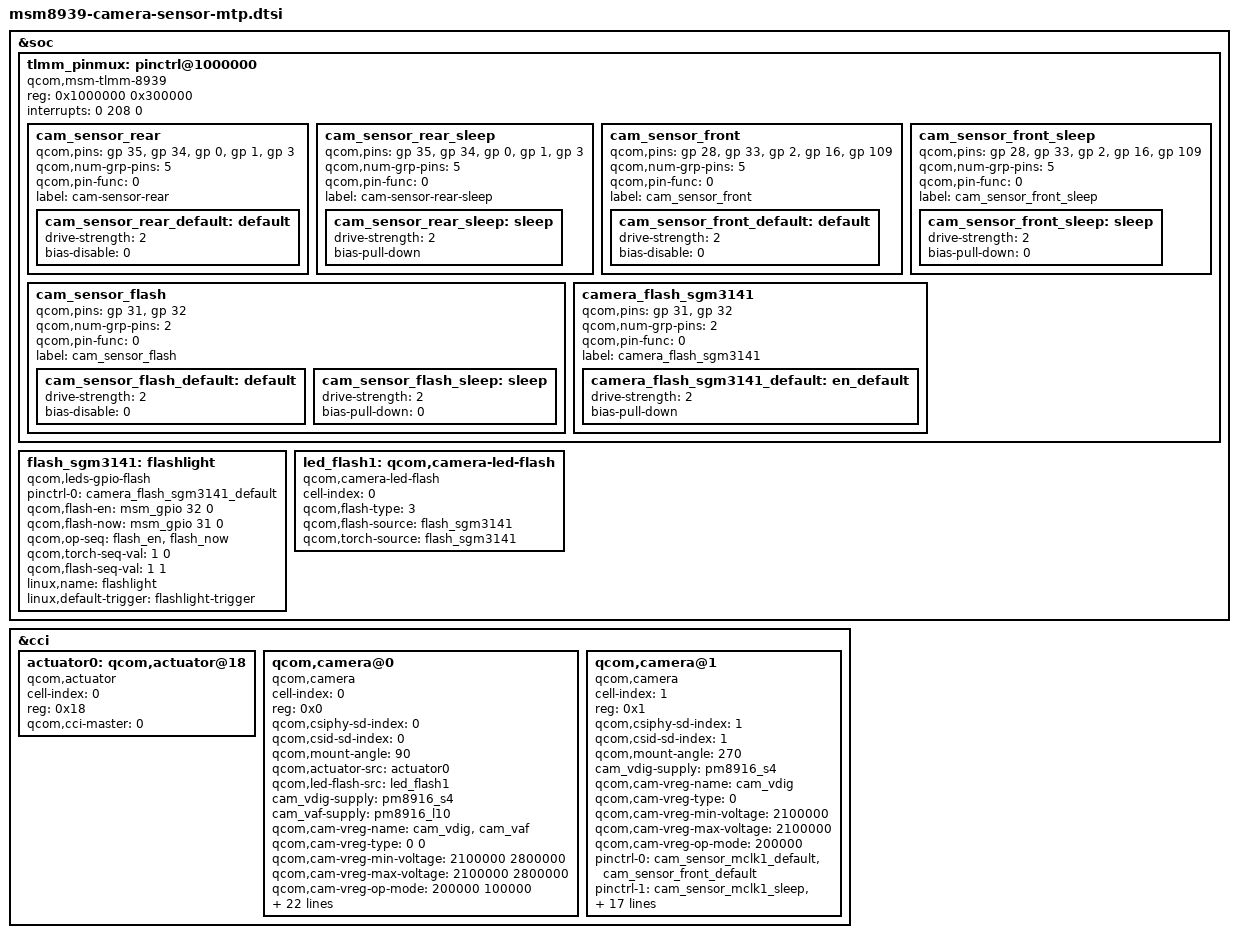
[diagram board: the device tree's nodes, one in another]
/*
 * Copyright (c) 2014, The Linux Foundation. All rights reserved.
 *
 * This program is free software; you can redistribute it and/or modify
 * it under the terms of the GNU General Public License version 2 and
 * only version 2 as published by the Free Software Foundation.
 *
 * This program is distributed in the hope that it will be useful,
 * but WITHOUT ANY WARRANTY; without even the implied warranty of
 * MERCHANTABILITY or FITNESS FOR A PARTICULAR PURPOSE.  See the
 * GNU General Public License for more details.
 */
	
&tlmm_pinmux {
 	camera_flash_sgm3141 {
 		/* FLSH_RESET,FLASH_EN,FLASH_NOW */
 		qcom,pins = <&gp 31>,<&gp 32> ;
 		qcom,num-grp-pins = <2>;
 		qcom,pin-func = <0>;
 		label = "camera_flash_sgm3141";
 		/* active state */
 		camera_flash_sgm3141_default: en_default {
 			drive-strength = <2>; /* 2 MA */
 			bias-pull-down;
 		};
 	};
};

&soc {
	tlmm_pinmux: pinctrl@1000000 {
		compatible = "qcom,msm-tlmm-8939", "qcom,msm-tlmm-8916";
		reg = <0x1000000 0x300000>;
		interrupts = <0 208 0>;

		cam_sensor_rear {
			/* RESET, STANDBY */
			qcom,pins =  <&gp 35>, <&gp 34>, <&gp 0>, <&gp 1>, <&gp 3>; /*add gp 0 1 3 by congshan */
			qcom,num-grp-pins = <5>;
			qcom,pin-func = <0>;
			label = "cam-sensor-rear";
			/* active state */
			cam_sensor_rear_default: default {
				drive-strength = <2>; /* 2 MA */
				bias-disable = <0>; /* No PULL */
			};
		};

		cam_sensor_rear_sleep {
			/* RESET, STANDBY */
			qcom,pins =  <&gp 35>, <&gp 34>, <&gp 0>, <&gp 1>, <&gp 3>; /*add gp 0 1 3 by congshan */
			qcom,num-grp-pins = <5>;
			qcom,pin-func = <0>;
			label = "cam-sensor-rear-sleep";
			/*suspend state */
			cam_sensor_rear_sleep: sleep {
				drive-strength = <2>; /* 2 MA */
				bias-pull-down; /* PULL DOWN */
			};
		};

		cam_sensor_front {
			/* RESET, STANDBY */
			qcom,pins = <&gp 28>, <&gp 33>, <&gp 2>, <&gp 16>, <&gp 109>; /*add gp 2 16 109 by congshan */
			qcom,num-grp-pins = <5>;
			qcom,pin-func = <0>;
			label = "cam_sensor_front";
			/* active state */
			cam_sensor_front_default: default {
				drive-strength = <2>; /* 2 MA */
				bias-disable = <0>; /* No PULL */
			};
		};

		cam_sensor_front_sleep {
			/* RESET, STANDBY */
			qcom,pins = <&gp 28>, <&gp 33>, <&gp 2>, <&gp 16>, <&gp 109>; /*add gp 2 16 109 by congshan */
			qcom,num-grp-pins = <5>;
			qcom,pin-func = <0>;
			label = "cam_sensor_front_sleep";
			/*suspend state */
			cam_sensor_front_sleep: sleep {
				drive-strength = <2>; /* 2 MA */
				bias-pull-down = <0>; /* PULL DOWN */
			};
		};

		cam_sensor_flash {
			/* FLSH_RESET,FLASH_EN,FLASH_NOW */
			qcom,pins =  <&gp 31>,<&gp 32> ;//change by congshan
			qcom,num-grp-pins = <2>;
			qcom,pin-func = <0>;
			label = "cam_sensor_flash";
			/* active state */
			cam_sensor_flash_default: default {
				drive-strength = <2>; /* 2 MA */
				bias-disable = <0>; /* No PULL */
			};
			/*suspended state */
			cam_sensor_flash_sleep: sleep {
				drive-strength = <2>; /* 2 MA */
				bias-pull-down = <0>; /* PULL DOWN */
			};
		};
	};
 	flash_sgm3141:flashlight {
 		compatible = "qcom,leds-gpio-flash";
 		status = "okay";
 		pinctrl-names = "flash_default";
 		pinctrl-0 = <&camera_flash_sgm3141_default>;
 		qcom,flash-en = <&msm_gpio 32 0>;
 		qcom,flash-now = <&msm_gpio 31 0>;
		qcom,op-seq = "flash_en", "flash_now";
		qcom,torch-seq-val = <1 0>;
		qcom,flash-seq-val = <1 1>;
 		linux,name = "flashlight";
 		linux,default-trigger = "flashlight-trigger";
 	};

 	led_flash1: qcom,camera-led-flash {
 		cell-index = <0>;
 		compatible = "qcom,camera-led-flash";
 		qcom,flash-type = <3>;
 		qcom,flash-source = <&flash_sgm3141>;
 		qcom,torch-source = <&flash_sgm3141>;
 	};
};

&cci {
	actuator0: qcom,actuator@18 {
		cell-index = <0>;
		reg = <0x18>;
		compatible = "qcom,actuator";
		qcom,cci-master = <0>;
	};	

/*
	 eeprom0: qcom,eeprom@20 {
		cell-index = <0>;
		reg = <0x20>;
		qcom,eeprom-name = "sonyimx135";
		compatible = "qcom,eeprom";
		qcom,slave-addr = <0x20>;
		qcom,cci-master = <0>;
		qcom,num-blocks = <16>;

		qcom,page0 = <1 0x3b02 2 0x10 1 5>;
		qcom,pageen0 = <1 0x3b00 2 0x01 1 5>;
		qcom,poll0 = <1 0x3b01 2 0x01 1 5>;
		qcom,mem0 = <8 0x3b04 2 0 1 0>;

		qcom,page1 = <1 0x3b02 2 0x0F 1 5>;
		qcom,pageen1 = <1 0x3b00 2 0x01 1 5>;
		qcom,poll1 = <1 0x3b01 2 0x01 1 5>;
		qcom,mem1 = <8 0x3b04 2 0 1 0>;

		qcom,page2 = <1 0x3b02 2 0x0E 1 5>;
		qcom,pageen2 = <1 0x3b00 2 0x01 1 5>;
		qcom,poll2 = <1 0x3b01 2 0x01 1 5>;
		qcom,mem2 = <8 0x3b04 2 0 1 0>;

		qcom,page3 = <1 0x3b02 2 0x0D 1 5>;
		qcom,pageen3 = <1 0x3b00 2 0x01 1 5>;
		qcom,poll3 = <1 0x3b01 2 0x01 1 5>;
		qcom,mem3 = <8 0x3b04 2 0 1 0>;

		qcom,page4 = <1 0x3b02 2 0x12 1 5>;
		qcom,pageen4 = <1 0x3b00 2 0x01 1 5>;
		qcom,poll4 = <1 0x3b01 2 0x01 1 5>;
		qcom,mem4 = <7 0x3b09 2 0 1 0>;

		qcom,page5 = <1 0x3b02 2 0x11 1 5>;
		qcom,pageen5 = <1 0x3b00 2 0x01 1 5>;
		qcom,poll5 = <1 0x3b01 2 0x01 1 5>;
		qcom,mem5 = <7 0x3b09 2 0 1 0>;

		qcom,page6 = <1 0x3b02 2 0x10 1 5>;
		qcom,pageen6 = <1 0x3b00 2 0x01 1 5>;
		qcom,poll6 = <1 0x3b01 2 0x01 1 5>;
		qcom,mem6 = <7 0x3b09 2 0 1 0>;

		qcom,page7 = <1 0x3b02 2 0x09 1 5>;
		qcom,pageen7 = <1 0x3b00 2 0x01 1 5>;
		qcom,poll7 = <1 0x3b01 2 0x01 1 5>;
		qcom,mem7 = <7 0x3b09 2 0 1 0>;

		qcom,page8 = <1 0x3b02 2 0x01 1 5>;
		qcom,pageen8 = <1 0x3b00 2 0x01 1 5>;
		qcom,poll8 = <1 0x3b01 2 0x01 1 5>;
		qcom,mem8 = <64 0x3b04 2 0 1 0>;

		qcom,page9 = <1 0x3b02 2 0x02 1 5>;
		qcom,pageen9 = <1 0x3b00 2 0x01 1 5>;
		qcom,poll9 = <1 0x3b01 2 0x01 1 5>;
		qcom,mem9 = <64 0x3b04 2 0 1 0>;

		qcom,page10 = <1 0x3b02 2 0x03 1 5>;
		qcom,pageen10 = <1 0x3b00 2 0x01 1 5>;
		qcom,poll10 = <1 0x3b01 2 0x01 1 5>;
		qcom,mem10 = <64 0x3b04 2 0 1 0>;

		qcom,page11 = <1 0x3b02 2 0x04 1 5>;
		qcom,pageen11 = <1 0x3b00 2 0x01 1 5>;
		qcom,poll11 = <1 0x3b01 2 0x01 1 5>;
		qcom,mem11 = <64 0x3b04 2 0 1 0>;

		qcom,page12 = <1 0x3b02 2 0x05 1 5>;
		qcom,pageen12 = <1 0x3b00 2 0x01 1 5>;
		qcom,poll12 = <1 0x3b01 2 0x01 1 5>;
		qcom,mem12 = <64 0x3b04 2 0 1 0>;

		qcom,page13 = <1 0x3b02 2 0x06 1 5>;
		qcom,pageen13 = <1 0x3b00 2 0x01 1 5>;
		qcom,poll13 = <1 0x3b01 2 0x01 1 5>;
		qcom,mem13 = <64 0x3b04 2 0 1 0>;

		qcom,page14 = <1 0x3b02 2 0x07 1 5>;
		qcom,pageen14 = <1 0x3b00 2 0x01 1 5>;
		qcom,poll14 = <1 0x3b01 2 0x01 1 5>;
		qcom,mem14 = <64 0x3b04 2 0 1 0>;

		qcom,page15 = <1 0x3b02 2 0x08 1 5>;
		qcom,pageen15 = <1 0x3b00 2 0x01 1 5>;
		qcom,poll15 = <1 0x3b01 2 0x01 1 5>;
		qcom,mem15 = <56 0x3b04 2 0 1 0>;

		cam_vdig-supply = <&pm8916_s4>;
		cam_vio-supply = <&pm8916_l17>;
		cam_vana-supply = <&pm8916_l6>;
		qcom,cam-vreg-name = "cam_vdig", "cam_vio", "cam_vana";
		qcom,cam-vreg-type = <0 1 0>;
		qcom,cam-vreg-min-voltage = <2100000 0 2850000 2800000>;
		qcom,cam-vreg-max-voltage = <2100000 0 2850000 2800000>;
		qcom,cam-vreg-op-mode = <200000 0 80000 100000>;
		pinctrl-names = "cam_default", "cam_suspend";
		pinctrl-0 = <&cam_sensor_mclk0_default &cam_sensor_rear_default>;
		pinctrl-1 = <&cam_sensor_mclk0_sleep &cam_sensor_rear_sleep>;
		qcom,gpio-no-mux = <0>;
		gpios = <&msm_gpio 26 0>,
			<&msm_gpio 35 0>,
			<&msm_gpio 34 0>;
		qcom,gpio-reset = <1>;
		qcom,gpio-standby = <2>;
		qcom,gpio-req-tbl-num = <0 1 2>;
		qcom,gpio-req-tbl-flags = <1 0 0>;
		qcom,gpio-req-tbl-label = "CAMIF_MCLK",
			"CAM_RESET1",
			"CAM_STANDBY";
		qcom,gpio-set-tbl-num = <1 1>;
		qcom,gpio-set-tbl-flags = <0 2>;
		qcom,gpio-set-tbl-delay = <1000 4000>;
		qcom,csi-lane-assign = <0x4320>;
		qcom,csi-lane-mask = <0x3>;
		qcom,cam-power-seq-type = "sensor_vreg", "sensor_vreg", "sensor_vreg",
			"sensor_gpio", "sensor_gpio" , "sensor_clk";
		qcom,cam-power-seq-val = "cam_vdig", "cam_vana", "cam_vio",
			"sensor_gpio_reset", "sensor_gpio_standby","sensor_cam_mclk";
		qcom,cam-power-seq-cfg-val = <1 1 1 1 1 24000000>;
		qcom,cam-power-seq-delay = <1 1 1 30 30 5>;
	};*/
/*
	//added by congshan start
	eeprom0: qcom,eeprom@20 {
		cell-index = <0>;
		reg = <0x20>;
		qcom,eeprom-name = "zte_imx135_bu64291gwz";
		compatible = "qcom,eeprom";
		qcom,slave-addr = <0x20>;
		qcom,cci-master = <0>;
		qcom,num-blocks = <6>;
		qcom,page0 = <0 0x00 1 0xf 1 1>;
		qcom,poll0 = <0 0x0 2 0 1 1>;
		qcom,saddr0 =<0xA0>;
		qcom,mem0 = <23 0x00 1 0 1 1>;
		qcom,page1 = <0 0x0100 2 0x01 1 1>;
		qcom,poll1 = <0 0x0 2 0 1 1>;
		qcom,saddr1 =<0xA4>;
		qcom,mem1 = <255 0x00 1 0 1 0>;
		qcom,page2 = <0 0x0100 2 0x01 1 1>;
		qcom,poll2 = <0 0x0 2 0 1 1>;
		qcom,saddr2 =<0xA6>;
		qcom,mem2 = <255 0x00 1 0 1 0>;
		qcom,page3 = <0 0x0100 2 0x01 1 1>;
		qcom,poll3 = <0 0x0 2 0 1 1>;
		qcom,saddr3 =<0xA8>;
		qcom,mem3 = <255 0x00 1 0 1 0>;
		qcom,page4 = <0 0x0100 2 0x01 1 1>;
		qcom,poll4 = <0 0x0 2 0 1 1>;
		qcom,saddr4 =<0xAA>;
		qcom,mem4 = <255 0x00 1 0 1 0>;
		qcom,page5 = <0 0x0100 2 0x01 1 1>;
		qcom,poll5 = <0 0x0 2 0 1 1>;
		qcom,saddr5 =<0xAC>;
		qcom,mem5 = <85 0x00 1 0 1 0>;
		cam_vdig-supply = <&pm8916_s4>;
		cam_vaf-supply = <&pm8916_l10>;
		qcom,cam-vreg-name ="cam_vdig","cam_vaf";
		qcom,cam-vreg-type = <0 0>;
		qcom,cam-vreg-min-voltage = <2100000 2800000>;
		qcom,cam-vreg-max-voltage = <2100000 2800000>;
		qcom,cam-vreg-op-mode = <200000 100000>;
		pinctrl-names = "cam_default", "cam_suspend";
		pinctrl-0 = <&cam_sensor_mclk0_default &cam_sensor_rear_default>;
		pinctrl-1 = <&cam_sensor_mclk0_sleep &cam_sensor_rear_sleep>;
		gpios = <&msm_gpio 26 0>,
			<&msm_gpio 35 0>,
			<&msm_gpio 34 0>,
			<&msm_gpio 3 0>,
			<&msm_gpio 1 0>,
			<&msm_gpio 0 0>;			
		qcom,gpio-reset = <1>;
		qcom,gpio-standby = <2>;
		qcom,gpio-vana = <3>;	
		qcom,gpio-vdig = <4>;	
		qcom,gpio-vio = <5>;	
		qcom,gpio-req-tbl-num = <0 1 2 3 4 5>;
		qcom,gpio-req-tbl-flags = <1 0 0 0 0 0>;
		qcom,gpio-req-tbl-label = "CAMIF_MCLK",
			"CAM_RESET",
			"CAM_STANDBY",
			"CAM_VANA",
            "CAM_VDIG",
	        "CAM_VIO";
		qcom,cam-power-seq-type = "sensor_vreg", "sensor_vreg", "sensor_gpio", 
				"sensor_gpio", "sensor_gpio", "sensor_gpio",
				"sensor_gpio", "sensor_gpio", "sensor_gpio",
				"sensor_gpio", "sensor_gpio", "sensor_gpio", 
		        "sensor_clk", "sensor_i2c_mux";
		qcom,cam-power-seq-val = "cam_vdig", "cam_vaf", "sensor_gpio_vdig", 
				"sensor_gpio_vdig", "sensor_gpio_vio", "sensor_gpio_vio", 
				"sensor_gpio_vana", "sensor_gpio_vana", "sensor_gpio_reset",
		        "sensor_gpio_reset",
		        "sensor_gpio_standby",
		        "sensor_gpio_standby",
		        "sensor_cam_mclk",
		        "none";
		qcom,cam-power-seq-cfg-val = <1 1 0 1 0 1 0 1 0 1 0 1 23880000 0>;
		qcom,cam-power-seq-delay =   <1 1 1 1 1 1 1 1 1 30 1 30 1 0>;
		status = "ok";
		clocks = <&clock_gcc clk_mclk0_clk_src>,
				<&clock_gcc clk_gcc_camss_mclk0_clk>;
		clock-names = "cam_src_clk", "cam_clk";
	};
//added by congshan end

	qcom,camera@78 {
		compatible = "ovti,ov5645";
		reg = <0x78 0x0>;
		qcom,slave-id = <0x78 0x300a 0x5645>;
		qcom,csiphy-sd-index = <1>;
		qcom,csid-sd-index = <1>;
		qcom,mount-angle = <90>;
		qcom,sensor-name = "ov5645";
		cam_vdig-supply = <&pm8916_s4>;
		cam_vana-supply = <&pm8916_l17>;
		cam_vio-supply = <&pm8916_l6>;
		qcom,cam-vreg-name = "cam_vdig", "cam_vio", "cam_vana";
		qcom,cam-vreg-type = <0 1 0>;
		qcom,cam-vreg-min-voltage = <2100000 0 2850000>;
		qcom,cam-vreg-max-voltage = <2100000 0 2850000>;
		qcom,cam-vreg-op-mode = <200000 0 80000>;
		pinctrl-names = "cam_default", "cam_suspend";
		pinctrl-0 = <&cam_sensor_mclk1_default &cam_sensor_front_default>;
		pinctrl-1 = <&cam_sensor_mclk1_sleep &cam_sensor_front_sleep>;
		gpios = <&msm_gpio 27 0>,
			<&msm_gpio 28 0>,
			<&msm_gpio 33 0>;
		qcom,gpio-reset = <1>;
		qcom,gpio-standby = <2>;
		qcom,gpio-req-tbl-num = <0 1 2>;
		qcom,gpio-req-tbl-flags = <1 0 0>;
		qcom,gpio-req-tbl-label = "CAMIF_MCLK",
					"CAM_RESET",
					"CAM_STANDBY";
		qcom,gpio-set-tbl-num = <1 1>;
		qcom,gpio-set-tbl-flags = <0 2>;
		qcom,gpio-set-tbl-delay = <1000 4000>;
		qcom,csi-lane-assign = <0x4320>;
		qcom,csi-lane-mask = <0x3>;
		qcom,sensor-position = <1>;
		qcom,sensor-mode = <0>;
		qcom,cci-master = <0>;
		qcom,mclk-23880000;
		clocks = <&clock_gcc clk_mclk1_clk_src>,
				<&clock_gcc clk_gcc_camss_mclk1_clk>;
		clock-names = "cam_src_clk", "cam_clk";
	};
*/
	qcom,camera@0 {
		cell-index = <0>;
		compatible = "qcom,camera";
		reg = <0x0>;
		qcom,csiphy-sd-index = <0>;
		qcom,csid-sd-index = <0>;
		qcom,mount-angle = <90>;
		qcom,actuator-src = <&actuator0>;
		qcom,led-flash-src = <&led_flash1>;
		//qcom,eeprom-src = <&eeprom0>;
		cam_vdig-supply = <&pm8916_s4>;
		cam_vaf-supply = <&pm8916_l10>;
		qcom,cam-vreg-name ="cam_vdig","cam_vaf";
		qcom,cam-vreg-type = < 0 0>;
		qcom,cam-vreg-min-voltage = <2100000 2800000>;
		qcom,cam-vreg-max-voltage = <2100000 2800000>;
		qcom,cam-vreg-op-mode = <200000 100000>;
		pinctrl-names = "cam_default", "cam_suspend";
		pinctrl-0 = <&cam_sensor_mclk0_default &cam_sensor_rear_default>;
		pinctrl-1 = <&cam_sensor_mclk0_sleep &cam_sensor_rear_sleep>;
		gpios = <&msm_gpio 26 0>,
			<&msm_gpio 35 0>,
			<&msm_gpio 34 0>,
			<&msm_gpio 3 0>,
			<&msm_gpio 1 0>,
			<&msm_gpio 0 0>;			
		qcom,gpio-reset = <1>;
		qcom,gpio-standby = <2>;
		qcom,gpio-vana = <3>;	
		qcom,gpio-vdig = <4>;	
		qcom,gpio-vio = <5>;	
		qcom,gpio-req-tbl-num = <0 1 2 3 4 5>;
		qcom,gpio-req-tbl-flags = <1 0 0 0 0 0>;
		qcom,gpio-req-tbl-label = "CAMIF_MCLK",
			"CAM_RESET1",
			"CAM_STANDBY",
			"CAM_VANA",
                      "CAM_VDIG",
	               "CAM_VIO";				
		qcom,sensor-position = <0>;
		qcom,sensor-mode = <0>;
		qcom,cci-master = <0>;
		qcom,mclk-23880000;
		status = "ok";
		clocks = <&clock_gcc clk_mclk0_clk_src>,
				<&clock_gcc clk_gcc_camss_mclk0_clk>;
		clock-names = "cam_src_clk", "cam_clk";
	};

	qcom,camera@1 {
		cell-index = <1>;
		compatible = "qcom,camera";
		reg = <0x1>;
		qcom,csiphy-sd-index = <1>;
		qcom,csid-sd-index = <1>;
		qcom,mount-angle = <270>;
		cam_vdig-supply = <&pm8916_s4>;
		//cam_vana-supply = <&pm8916_l17>;
		//cam_vio-supply = <&pm8916_l6>;
		qcom,cam-vreg-name = "cam_vdig";
		qcom,cam-vreg-type = <0>;
		qcom,cam-vreg-min-voltage = <2100000>;
		qcom,cam-vreg-max-voltage = <2100000>;
		qcom,cam-vreg-op-mode = <200000>;
		pinctrl-names = "cam_default", "cam_suspend";
		pinctrl-0 = <&cam_sensor_mclk1_default &cam_sensor_front_default>;
		pinctrl-1 = <&cam_sensor_mclk1_sleep &cam_sensor_front_sleep>;
		gpios = <&msm_gpio 27 0>,
			<&msm_gpio 28 0>,
			<&msm_gpio 33 0>,
			<&msm_gpio 2 0>,
			<&msm_gpio 16 0>;
		qcom,gpio-reset = <1>;
		qcom,gpio-standby = <2>;
		qcom,gpio-vana = <3>;	
		qcom,gpio-vio = <4>;
		qcom,gpio-req-tbl-num = <0 1 2 3 4>;
		qcom,gpio-req-tbl-flags = <1 0 0 0 0>;
		qcom,gpio-req-tbl-label = "CAMIF_MCLK",
			"CAM_RESET",
			"CAM_STANDBY",
			"CAM_VANA",
			"CAM_VIO";
		qcom,sensor-position = <1>;
		qcom,sensor-mode = <1>;				
		qcom,cci-master = <0>;
		qcom,mclk-23880000;
		status = "ok";
		clocks = <&clock_gcc clk_mclk1_clk_src>,
				<&clock_gcc clk_gcc_camss_mclk1_clk>;
		clock-names = "cam_src_clk", "cam_clk";
	};
};
